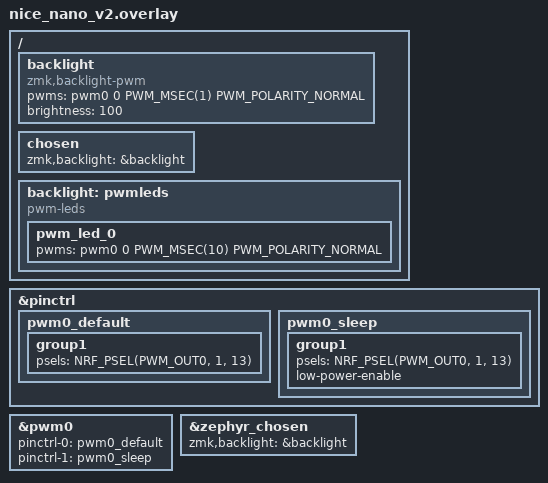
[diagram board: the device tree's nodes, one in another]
&pinctrl {
    // Other pinctrl definitions for other hardware
    pwm0_default: pwm0_default {
        group1 {
            psels = <NRF_PSEL(PWM_OUT0, 1, 13)>;
        };
    };
    pwm0_sleep: pwm0_sleep {
        group1 {
            psels = <NRF_PSEL(PWM_OUT0, 1, 13)>;
            low-power-enable;
        };
    };
};

&pwm0 {
    status = "okay";
    pinctrl-0 = <&pwm0_default>;
    pinctrl-1 = <&pwm0_sleep>;
    pinctrl-names = "default", "sleep";
};


/ {
    backlight: backlight {
        compatible = "zmk,backlight-pwm";
        pwms = <&pwm0 0 PWM_MSEC(1) PWM_POLARITY_NORMAL>;
        brightness = <100>;
    };

    chosen {
        zmk,backlight = &backlight;
    };
};

/ {
    backlight: pwmleds {
        compatible = "pwm-leds";
        pwm_led_0 {
            pwms = <&pwm0 0 PWM_MSEC(10) PWM_POLARITY_NORMAL>;
        };
    };
};

&zephyr_chosen {
    zmk,backlight = &backlight;
};
